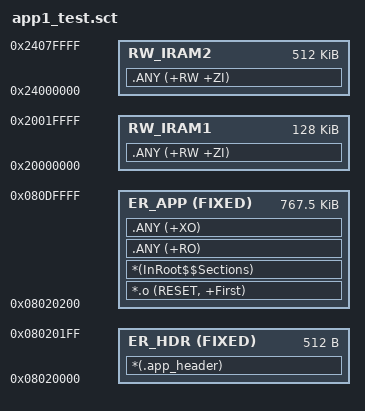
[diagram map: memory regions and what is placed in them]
; SLOT_TOTAL_SIZE = 0x000E0000
; TRAILER_SIZE    = 0x00020000     ; 例子：预留 1 个 sector
; IMAGE_MAX_SIZE  = 0x000C0000     ; 0xE0000 - 0x20000
; HDR_SIZE        = 0x00000200
; ER_APP_SIZE     = 0x000BFE00     ; 0xC0000 - 0x200

LR_IROM1 0x08020000 0x000C0000  {

  ER_HDR  0x08020000 FIXED 0x00000200  {
    *(.app_header)
  }

  ER_APP  0x08020200 FIXED 0x000BFE00  {
    *.o (RESET, +First)
    *(InRoot$$Sections)
    .ANY (+RO)
    .ANY (+XO)
  }

  RW_IRAM1 0x20000000 0x00020000  { .ANY (+RW +ZI) }
  RW_IRAM2 0x24000000 0x00080000  { .ANY (+RW +ZI) }
}
